AUTOSAR XML (schema 00050)
package /Components
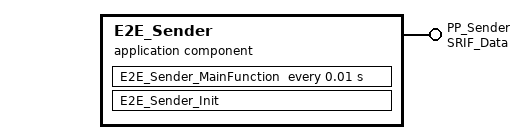
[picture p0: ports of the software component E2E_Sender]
  application sw component type E2E_Sender
    provide port PP_Sender: nonqueued-sender-com-spec{data-element=Data, uses-end-to-end-protection=true, init-value=0}, provided-interface=SRIF_Data
    behavior E2E_Sender_IB: handle-termination-and-restart=NO-SUPPORT
      timing event TE_E2E_Sender_MainFunction: start-on-event=E2E_Sender_MainFunction, period=0.01
      runnable E2E_Sender_Init
      runnable E2E_Sender_MainFunction
        data-send-points:
          access OUT_PP_Sender_Data: accessed-variable=PP_Sender.Data
